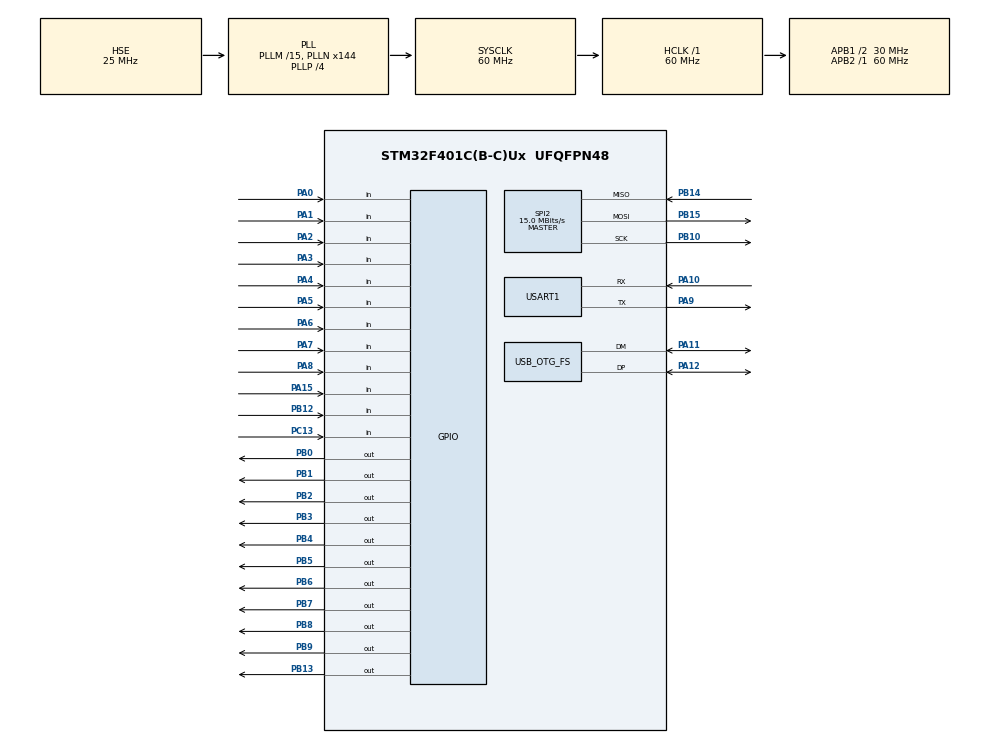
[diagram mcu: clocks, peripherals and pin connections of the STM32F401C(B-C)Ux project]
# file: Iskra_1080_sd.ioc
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FATFS._FS_EXFAT=1
FATFS._MAX_SS=4096
FATFS._MULTI_PARTITION=0
FATFS._USE_LFN=2
Mcu.Family=STM32F4
Mcu.Name=STM32F401C(B-C)Ux
Mcu.Package=UFQFPN48
NVIC.OTG_FS_IRQn=true\:0\:0\:false\:false\:true\:false\:true\:true
NVIC.PriorityGroup=NVIC_PRIORITYGROUP_4
PA0-WKUP.Signal=GPIO_Input
PA1.Signal=GPIO_Input
PA10.Mode=Asynchronous
PA10.Signal=USART1_RX
PA11.Mode=Host_Only
PA11.Signal=USB_OTG_FS_DM
PA12.Mode=Host_Only
PA12.Signal=USB_OTG_FS_DP
PA13.Mode=Serial_Wire
PA13.Signal=SYS_JTMS-SWDIO
PA14.Mode=Serial_Wire
PA14.Signal=SYS_JTCK-SWCLK
PA15.Signal=GPIO_Input
PA2.Signal=GPIO_Input
PA3.Signal=GPIO_Input
PA4.Signal=GPIO_Input
PA5.Signal=GPIO_Input
PA6.Signal=GPIO_Input
PA7.Signal=GPIO_Input
PA8.GPIO_PuPd=GPIO_NOPULL
PA8.Signal=GPIO_Input
PA9.Mode=Asynchronous
PA9.Signal=USART1_TX
PB0.GPIO_Speed=GPIO_SPEED_FREQ_VERY_HIGH
PB0.Signal=GPIO_Output
PB1.GPIO_Speed=GPIO_SPEED_FREQ_VERY_HIGH
PB1.Signal=GPIO_Output
PB10.Mode=Full_Duplex_Master
PB10.Signal=SPI2_SCK
PB12.GPIO_PuPd=GPIO_PULLUP
PB12.Signal=GPIO_Input
PB13.GPIO_Speed=GPIO_SPEED_FREQ_VERY_HIGH
PB13.Signal=GPIO_Output
PB14.Mode=Full_Duplex_Master
PB14.Signal=SPI2_MISO
PB15.Mode=Full_Duplex_Master
PB15.Signal=SPI2_MOSI
PB2.GPIO_Speed=GPIO_SPEED_FREQ_VERY_HIGH
PB2.Signal=GPIO_Output
PB3.GPIO_Speed=GPIO_SPEED_FREQ_VERY_HIGH
PB3.Signal=GPIO_Output
PB4.GPIO_Speed=GPIO_SPEED_FREQ_VERY_HIGH
PB4.Signal=GPIO_Output
PB5.GPIO_Speed=GPIO_SPEED_FREQ_VERY_HIGH
PB5.Signal=GPIO_Output
PB6.GPIO_Speed=GPIO_SPEED_FREQ_VERY_HIGH
PB6.Signal=GPIO_Output
PB7.GPIO_Speed=GPIO_SPEED_FREQ_VERY_HIGH
PB7.Signal=GPIO_Output
PB8.GPIO_Speed=GPIO_SPEED_FREQ_VERY_HIGH
PB8.Signal=GPIO_Output
PB9.GPIO_Speed=GPIO_SPEED_FREQ_VERY_HIGH
PB9.Signal=GPIO_Output
PC13-ANTI_TAMP.Signal=GPIO_Input
PC14-OSC32_IN.Mode=LSE-External-Oscillator
PC14-OSC32_IN.Signal=RCC_OSC32_IN
PC15-OSC32_OUT.Mode=LSE-External-Oscillator
PC15-OSC32_OUT.Signal=RCC_OSC32_OUT
PH0\ -\ OSC_IN.Mode=HSE-External-Oscillator
PH0\ -\ OSC_IN.Signal=RCC_OSC_IN
PH1\ -\ OSC_OUT.Mode=HSE-External-Oscillator
PH1\ -\ OSC_OUT.Signal=RCC_OSC_OUT
ProjectManager.HeapSize=0x0
ProjectManager.StackSize=0x1000
ProjectManager.TargetToolchain=Makefile
RCC.48MHZClocksFreq_Value=48000000
RCC.AHBFreq_Value=60000000
RCC.APB1CLKDivider=RCC_HCLK_DIV2
RCC.APB1Freq_Value=30000000
RCC.APB1TimFreq_Value=60000000
RCC.APB2Freq_Value=60000000
RCC.APB2TimFreq_Value=60000000
RCC.CortexFreq_Value=60000000
RCC.HCLKFreq_Value=60000000
RCC.HSE_VALUE=25000000
RCC.HSI_VALUE=16000000
RCC.PLLM=15
RCC.PLLN=144
RCC.PLLP=RCC_PLLP_DIV4
RCC.PLLQ=5
RCC.SYSCLKFreq_VALUE=60000000
RCC.SYSCLKSource=RCC_SYSCLKSOURCE_PLLCLK
RCC.VCOOutputFreq_Value=240000000
SPI2.CalculateBaudRate=15.0 MBits/s
SPI2.Direction=SPI_DIRECTION_2LINES
SPI2.Mode=SPI_MODE_MASTER
SPI2.VirtualType=VM_MASTER
USART1.VirtualMode=VM_ASYNC
USB_HOST.USBH_HandleTypeDef=hUsbHostFS
USB_HOST.USBH_MAX_DATA_BUFFER=512
USB_HOST.VirtualModeFS=Msc
USB_OTG_FS.VirtualMode=Host_Only
USB_OTG_FS.phy_itface=HCD_PHY_EMBEDDED
VP_FATFS_VS_Generic.Mode=User_defined
VP_FATFS_VS_USB.Mode=USB
VP_USB_HOST_VS_USB_HOST_MSC_FS.Mode=MSC_FS
board=custom

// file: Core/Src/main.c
/* USER CODE BEGIN Header */
/**
 ******************************************************************************
 * @file           : main.c
 * @brief          : Main program body
 ******************************************************************************
 * @attention
 *
 * Copyright (c) 2023 STMicroelectronics.
 * All rights reserved.
 *
 * This software is licensed under terms that can be found in the LICENSE file
 * in the root directory of this software component.
 * If no LICENSE file comes with this software, it is provided AS-IS.
 *
 ******************************************************************************
 */
/* USER CODE END Header */
#include "main.h"
#include "fatfs.h"
#include "usb_host.h"

/* USER CODE BEGIN Includes */
#include "my.h"
/* USER CODE END Includes */

SPI_HandleTypeDef hspi2;

UART_HandleTypeDef huart1;

void SystemClock_Config(void);
static void MX_GPIO_Init(void);
static void MX_USART1_UART_Init(void);
static void MX_SPI2_Init(void);
void MX_USB_HOST_Process(void);

int main(void)
{

  /* MCU Configuration--------------------------------------------------------*/

  /* Reset of all peripherals, Initializes the Flash interface and the Systick. */
  HAL_Init();

  /* Configure the system clock */
  SystemClock_Config();

  /* Initialize all configured peripherals */
  MX_GPIO_Init();
  MX_USART1_UART_Init();
  MX_SPI2_Init();
  MX_FATFS_Init();
  MX_USB_HOST_Init();

  /* Infinite loop */
    while (1) {
    MX_USB_HOST_Process();

    /* USER CODE BEGIN 3 */
        //MyMain();
    }
  /* USER CODE END 3 */
}

void SystemClock_Config(void)
{
  RCC_OscInitTypeDef RCC_OscInitStruct = {0};
  RCC_ClkInitTypeDef RCC_ClkInitStruct = {0};

  /** Configure the main internal regulator output voltage
  */
  __HAL_RCC_PWR_CLK_ENABLE();
  __HAL_PWR_VOLTAGESCALING_CONFIG(PWR_REGULATOR_VOLTAGE_SCALE2);

  /** Initializes the RCC Oscillators according to the specified parameters
  * in the RCC_OscInitTypeDef structure.
  */
  RCC_OscInitStruct.OscillatorType = RCC_OSCILLATORTYPE_HSE;
  RCC_OscInitStruct.HSEState = RCC_HSE_ON;
  RCC_OscInitStruct.PLL.PLLState = RCC_PLL_ON;
  RCC_OscInitStruct.PLL.PLLSource = RCC_PLLSOURCE_HSE;
  RCC_OscInitStruct.PLL.PLLM = 15;
  RCC_OscInitStruct.PLL.PLLN = 144;
  RCC_OscInitStruct.PLL.PLLP = RCC_PLLP_DIV4;
  RCC_OscInitStruct.PLL.PLLQ = 5;
  if (HAL_RCC_OscConfig(&RCC_OscInitStruct) != HAL_OK)
  {
    Error_Handler();
  }

  /** Initializes the CPU, AHB and APB buses clocks
  */
  RCC_ClkInitStruct.ClockType = RCC_CLOCKTYPE_HCLK|RCC_CLOCKTYPE_SYSCLK
                              |RCC_CLOCKTYPE_PCLK1|RCC_CLOCKTYPE_PCLK2;
  RCC_ClkInitStruct.SYSCLKSource = RCC_SYSCLKSOURCE_PLLCLK;
  RCC_ClkInitStruct.AHBCLKDivider = RCC_SYSCLK_DIV1;
  RCC_ClkInitStruct.APB1CLKDivider = RCC_HCLK_DIV2;
  RCC_ClkInitStruct.APB2CLKDivider = RCC_HCLK_DIV1;

  if (HAL_RCC_ClockConfig(&RCC_ClkInitStruct, FLASH_LATENCY_1) != HAL_OK)
  {
    Error_Handler();
  }
}

static void MX_SPI2_Init(void)
{

  /* SPI2 parameter configuration*/
  hspi2.Instance = SPI2;
  hspi2.Init.Mode = SPI_MODE_MASTER;
  hspi2.Init.Direction = SPI_DIRECTION_2LINES;
  hspi2.Init.DataSize = SPI_DATASIZE_8BIT;
  hspi2.Init.CLKPolarity = SPI_POLARITY_LOW;
  hspi2.Init.CLKPhase = SPI_PHASE_1EDGE;
  hspi2.Init.NSS = SPI_NSS_SOFT;
  hspi2.Init.BaudRatePrescaler = SPI_BAUDRATEPRESCALER_2;
  hspi2.Init.FirstBit = SPI_FIRSTBIT_MSB;
  hspi2.Init.TIMode = SPI_TIMODE_DISABLE;
  hspi2.Init.CRCCalculation = SPI_CRCCALCULATION_DISABLE;
  hspi2.Init.CRCPolynomial = 10;
  if (HAL_SPI_Init(&hspi2) != HAL_OK)
  {
    Error_Handler();
  }

}

static void MX_USART1_UART_Init(void)
{

  huart1.Instance = USART1;
  huart1.Init.BaudRate = 115200;
  huart1.Init.WordLength = UART_WORDLENGTH_8B;
  huart1.Init.StopBits = UART_STOPBITS_1;
  huart1.Init.Parity = UART_PARITY_NONE;
  huart1.Init.Mode = UART_MODE_TX_RX;
  huart1.Init.HwFlowCtl = UART_HWCONTROL_NONE;
  huart1.Init.OverSampling = UART_OVERSAMPLING_16;
  if (HAL_UART_Init(&huart1) != HAL_OK)
  {
    Error_Handler();
  }

}

static void MX_GPIO_Init(void)
{
  GPIO_InitTypeDef GPIO_InitStruct = {0};

  /* GPIO Ports Clock Enable */
  __HAL_RCC_GPIOC_CLK_ENABLE();
  __HAL_RCC_GPIOH_CLK_ENABLE();
  __HAL_RCC_GPIOA_CLK_ENABLE();
  __HAL_RCC_GPIOB_CLK_ENABLE();

  /*Configure GPIO pin Output Level */
  HAL_GPIO_WritePin(GPIOB, GPIO_PIN_0|GPIO_PIN_1|GPIO_PIN_2|GPIO_PIN_13
                          |GPIO_PIN_3|GPIO_PIN_4|GPIO_PIN_5|GPIO_PIN_6
                          |GPIO_PIN_7|GPIO_PIN_8|GPIO_PIN_9, GPIO_PIN_RESET);

  /*Configure GPIO pin : PC13 */
  GPIO_InitStruct.Pin = GPIO_PIN_13;
  GPIO_InitStruct.Mode = GPIO_MODE_INPUT;
  GPIO_InitStruct.Pull = GPIO_NOPULL;
  HAL_GPIO_Init(GPIOC, &GPIO_InitStruct);

  /*Configure GPIO pins : PA0 PA1 PA2 PA3
                           PA4 PA5 PA6 PA7
                           PA8 PA15 */
  GPIO_InitStruct.Pin = GPIO_PIN_0|GPIO_PIN_1|GPIO_PIN_2|GPIO_PIN_3
                          |GPIO_PIN_4|GPIO_PIN_5|GPIO_PIN_6|GPIO_PIN_7
                          |GPIO_PIN_8|GPIO_PIN_15;
  GPIO_InitStruct.Mode = GPIO_MODE_INPUT;
  GPIO_InitStruct.Pull = GPIO_NOPULL;
  HAL_GPIO_Init(GPIOA, &GPIO_InitStruct);

  /*Configure GPIO pins : PB0 PB1 PB2 PB13
                           PB3 PB4 PB5 PB6
                           PB7 PB8 PB9 */
  GPIO_InitStruct.Pin = GPIO_PIN_0|GPIO_PIN_1|GPIO_PIN_2|GPIO_PIN_13
                          |GPIO_PIN_3|GPIO_PIN_4|GPIO_PIN_5|GPIO_PIN_6
                          |GPIO_PIN_7|GPIO_PIN_8|GPIO_PIN_9;
  GPIO_InitStruct.Mode = GPIO_MODE_OUTPUT_PP;
  GPIO_InitStruct.Pull = GPIO_NOPULL;
  GPIO_InitStruct.Speed = GPIO_SPEED_FREQ_VERY_HIGH;
  HAL_GPIO_Init(GPIOB, &GPIO_InitStruct);

  /*Configure GPIO pin : PB12 */
  GPIO_InitStruct.Pin = GPIO_PIN_12;
  GPIO_InitStruct.Mode = GPIO_MODE_INPUT;
  GPIO_InitStruct.Pull = GPIO_PULLUP;
  HAL_GPIO_Init(GPIOB, &GPIO_InitStruct);

}

void Error_Handler(void)
{
    __disable_irq();
    while (1) {
    }
}
